AUTOSAR XML (schema 00047)
package /ASW_CORE1
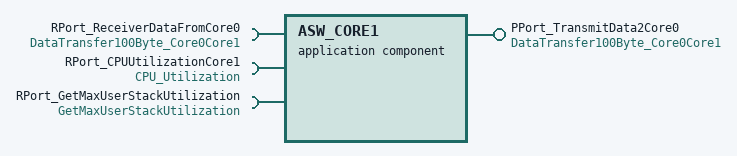
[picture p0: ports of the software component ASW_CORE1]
  application sw component type ASW_CORE1
    provide port PPort_TransmitData2Core0: provided-interface=DataTransfer100Byte_Core0Core1
    require port RPort_ReceiverDataFromCore0: required-interface=DataTransfer100Byte_Core0Core1
    require port RPort_CPUUtilizationCore1: required-interface=CPU_Utilization
    require port RPort_GetMaxUserStackUtilization: required-interface=GetMaxUserStackUtilization
    behavior SwcInternalBehavior
      4 x timing event:
        TimingEvent_0: start-on-event=RE_CORE1_SWC, period=0.01
        TimingEvent_1: start-on-event=MAIN_CORE1_1ms, period=0.001
        TimingEvent_2: start-on-event=GMAIN_CORE1_1ms, period=0.001
        TimingEvent_3: start-on-event=MAIN_CORE1_10ms, period=0.01
      4 x runnable:
        RE_CORE1_SWC: symbol=RE_CORE1_SWC_func
          data-receive-point-by-arguments:
            access DRPA_Data_ptr_0: accessed-variable=RPort_ReceiverDataFromCore0.Data_ptr
          data-send-points:
            access DSP_Data_ptr_0: accessed-variable=PPort_TransmitData2Core0.Data_ptr
          sync call SynchronousServerCallPoint: operation=RPort_CPUUtilizationCore1.CPU_Utilization
          sync call SynchronousServerCallPoint_0: operation=RPort_GetMaxUserStackUtilization.GetMaxUserStackUtilization
        MAIN_CORE1_1ms: symbol=MAIN_CORE1_1ms_func
        GMAIN_CORE1_1ms: symbol=GMAIN_CORE1_1ms_func
        MAIN_CORE1_10ms: symbol=MAIN_CORE1_10ms_func
